# alb32r003x register map
Vendor: ALB; Series: ALB RT SoC
CPU: ALB XF, little endian
Registers are 32-bit, access not given, reset 0x0 unless marked. A register's access mark holds for its fields unless they carry their own. Offsets are from the block's base; [hi:lo] are bit positions; {n}, {i} and the like mark numbered series; 'fields as' and 'values as' point back to an identical list.

## EFLASHC — EFLASHC: Embedded Flash Controller managing on-chip program memory
Base 0x23000000
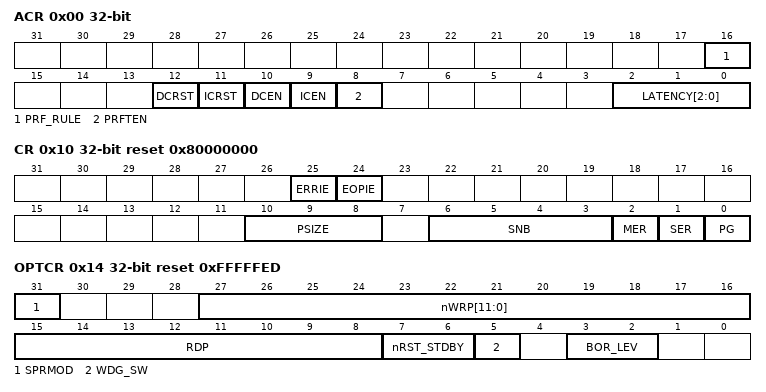
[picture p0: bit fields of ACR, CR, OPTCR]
0x00 ACR access per field — ACR: Access-control register for flash wait-state, cache and prefetch configuration
  [16] PRF_RULE rw — Instruction prefetching mode
    0=LESS (It initiates less prefetching mode and is suitable for those with many branch jumps scene.); 1=MORE (More initiate prefetching modes, suitable for sequential scenarios)
  [12] DCRST wo — Data cache reset enable
    0=NO (The data cache is not bit cleared); 1=YES (Data cache reset and clear)
  [11] ICRST wo — Data cache reset enable
    values as DCRST
  [10] DCEN rw — Data cache enable bit
    0=NO (The data cache is not enabled); 1=YES (Data cache enable)
  [9] ICEN rw — Data cache enable bit
    values as DCEN
  [8] PRFTEN rw — The instruction prefetches the enable bit
    0=NO (Instruction prefetching is not enabled); 1=YES (Instruction prefetch enable)
  [2:0] LATENCY[2:0] rw — These bits represent the bus clock cycle and the Flash access time the ratio.
    0=ZERO (Zero waiting period); 1=ONE (One waiting cycle)
0x04 KEYR wo — KEYR: Unlock-key register allowing secure write access to flash control registers
  [31:0] FKEYR[31:0] — The key used to unlock the FLASH_CR register must be written in the following order before the FLASH_CR register can be written to initiate erasure and write operations.
    0x45670123=KEY1; 0xCDEF89AB=KEY2
0x08 OPTKEYR wo — OPTKEYR: Option-byte key register enabling secure update of system configuration bytes
  [31:0] OPTKEYR[31:0] — To unlock the FLASH_OPTCR register, the optkey value must be written in the following order before writing to the FLASH_OPTCR register.
    0x8192A3B=KEY1; 0x4C5D6E7F=KEY2
0x0C SR ro — SR: Status register indicating flash busy, error and protection flags
  [16] BSY — Flash is busy
    0=NO (No Flash erase or write operations are currently being performed); 1=YES (The Flash erase and write operation is currently being executed)
0x10 CR rw reset 0x80000000 — CR: Control register for program/erase operations and global flash settings
  [25] ERRIE — Incorrect interrupt enable
    0=DISABLED (Error interrupts are prohibited); 1=ENABLED (Enable an error interrupt)
  [24] EOPIE — Interrupt the enable at the end of the operation
    0=DISABLED (Interruption is prohibited.); 1=ENABLED (Enabling causes an interruption)
  [10:8] PSIZE — Programming size
    0=x8 Programming; 1=x16 Programming; 2=x32 Programming; 3=x64 Programming; 4=x128 Programming
  [6:3] SNB — Sector number
    {v}=Sector {v} (v=0..11); {v}=INVALID (Invalid configuration, retained) (v=12..15)
  [2] MER — Whole-piece erasing enable
    1=ENABLED (Enable the entire Flash MAIN area to be erased); 0=DISABLED (Invalid)
  [1] SER — Sector erasure
    1=ENABLED (Enable sector erasure); 0=DISABLED (Invalid)
  [0] PG — Programming
    1=ENABLED (Enable Flash programming); 0=DISABLED (Invalid)
0x14 OPTCR rw reset 0xFFFFFED — OPTCR: Option-byte control register managing user, read-out and write-protection options
  [31] SPRMOD — Selection of nWPRi bit protection mode
    0=DISABLED (Prohibit PCROP. The nWPRi bit is used for sector i write protection); 1=ENABLED (Enable PCROP. The nWPRi bit is used for sector i PCROP protection.)
  [27:16] nWRP[11:0] — Write protection for sectors 11 to 0
    0=ACTIVE (PCROP protection for unactivated sector i); 1=INACTIVE (Activate the PCROP protection of sector i)
  [15:8] RDP — Read protection
    170=Level 0 (Read protection not activated); 204=Level 2 (Activate the chip read protection); 85=Level 1 (Activate the memory read protection)
  [7:6] nRST_STDBY — A reset event occurs when entering the stop mode
    0=YES (A reset occurs when entering the shutdown mode); 1=NO (No reset occurs)
  [5] WDG_SW — Hardware or software watchdog Settings
    0=HW (Hardware independent watchdog); 1=SW (Software-independent watchdog)
  [3:2] BOR_LEV — BOR reset level
    0=VBOR3 (Under-voltage threshold level 3); 1=VBOR2 (Under-voltage threshold level 2); 2=VBOR1 (Under-voltage threshold level 1); 3=CLOSE (When BOR is turned off, apply the POR/PDR reset threshold voltage)
